AUTOSAR XML (schema 4-2-2)
package /ComponentTypes
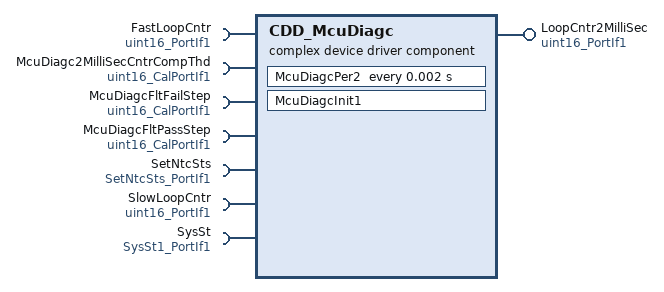
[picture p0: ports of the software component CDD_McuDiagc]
  complex device driver sw component type CDD_McuDiagc
    provide port LoopCntr2MilliSec: nonqueued-sender-com-spec{data-element=Val, init-value=0}, provided-interface=uint16_PortIf1
    7 x require port:
      FastLoopCntr: nonqueued-receiver-com-spec{data-element=Val, filter=data-filter-type=ALWAYS, init-value=0}, required-interface=uint16_PortIf1
      McuDiagc2MilliSecCntrCompThd: parameter-require-com-spec{init-value=5, parameter=Val}, required-interface=uint16_CalPortIf1
      McuDiagcFltFailStep: parameter-require-com-spec{init-value=16385, parameter=Val}, required-interface=uint16_CalPortIf1
      McuDiagcFltPassStep: parameter-require-com-spec{init-value=160, parameter=Val}, required-interface=uint16_CalPortIf1
      SetNtcSts: client-com-spec=Oper, required-interface=SetNtcSts_PortIf1
      SlowLoopCntr: nonqueued-receiver-com-spec{data-element=Val, filter=data-filter-type=ALWAYS, init-value=0}, required-interface=uint16_PortIf1
      SysSt: nonqueued-receiver-com-spec{data-element=Val, filter=data-filter-type=ALWAYS, init-value=3}, required-interface=SysSt1_PortIf1
    behavior CDD_McuDiagc_InternalBehavior
      ar-typed-per-instance-memorys:
        7 x data, all with sw-calibration-access=READ-ONLY:
          dMcuDiagcFastLoopCntrMax: type=uint16
          dMcuDiagcFastLoopCntrMin: type=uint16
          dMcuDiagcLoopCntr2MilliSecMotCtrlDif: type=uint16
          FastLoopCntrDiagcCfgd: type=uint8
          FastLoopCntrPrev: type=uint16
          LoopCntr2MilliSecStore: type=uint16
          LoopCntrPrev: type=uint16
      init event CDD_McuDiagc_InitEvent: start-on-event=McuDiagcInit1
      timing event TMT_McuDiagcPer2: start-on-event=McuDiagcPer2, period=0.002
      runnable McuDiagcInit1
      runnable McuDiagcPer2
        data-receive-point-by-arguments:
          access REC_FastLoopCntr_Val: accessed-variable=FastLoopCntr.Val
          access REC_SlowLoopCntr_Val: accessed-variable=SlowLoopCntr.Val
          access REC_SysSt_Val: accessed-variable=SysSt.Val
        data-send-points:
          access SEND_LoopCntr2MilliSec_Val: accessed-variable=LoopCntr2MilliSec.Val
        sync call SC_SetNtcSts_Oper: operation=SetNtcSts.Oper, timeout=0
  swc implementation CDD_McuDiagc_Implementation: behavior=CDD_McuDiagc_InternalBehavior
    code-descriptors:
      code Default: artifact-descriptors=autosar-engineering-object={short-label=Default, category=SWSRC}
